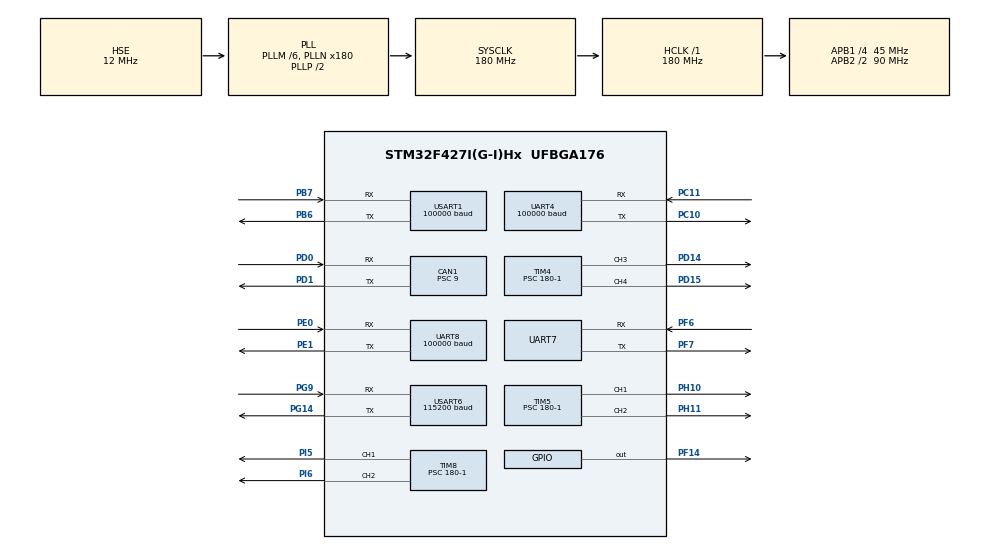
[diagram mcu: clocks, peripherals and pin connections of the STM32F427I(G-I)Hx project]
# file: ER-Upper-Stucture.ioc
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CAN1.BS1=CAN_BS1_3TQ
CAN1.CalculateBaudRate=1000000
CAN1.CalculateTimeBit=1000
CAN1.CalculateTimeQuantum=200.0
CAN1.Prescaler=9
Dma.Request0=USART1_RX
Dma.USART1_RX.0.Direction=DMA_PERIPH_TO_MEMORY
Dma.USART1_RX.0.FIFOMode=DMA_FIFOMODE_DISABLE
Dma.USART1_RX.0.Instance=DMA2_Stream2
Dma.USART1_RX.0.MemDataAlignment=DMA_MDATAALIGN_BYTE
Dma.USART1_RX.0.MemInc=DMA_MINC_ENABLE
Dma.USART1_RX.0.Mode=DMA_CIRCULAR
Dma.USART1_RX.0.PeriphDataAlignment=DMA_PDATAALIGN_BYTE
Dma.USART1_RX.0.PeriphInc=DMA_PINC_DISABLE
Dma.USART1_RX.0.Priority=DMA_PRIORITY_LOW
FREERTOS.INCLUDE_vTaskDelayUntil=1
FREERTOS.Tasks01=defaultTask,0,512,StartDefaultTask,As weak,NULL,Dynamic,NULL,NULL
FREERTOS.configENABLE_FPU=1
FREERTOS.configGENERATE_RUN_TIME_STATS=0
FREERTOS.configRECORD_STACK_HIGH_ADDRESS=1
FREERTOS.configTOTAL_HEAP_SIZE=65536
FREERTOS.configUSE_NEWLIB_REENTRANT=1
FREERTOS.configUSE_STATS_FORMATTING_FUNCTIONS=0
FREERTOS.configUSE_TRACE_FACILITY=0
Mcu.Family=STM32F4
Mcu.Name=STM32F427I(G-I)Hx
Mcu.Package=UFBGA176
NVIC.CAN1_RX0_IRQn=true\:0\:0\:true\:false\:true\:false\:true\:true\:true
NVIC.DMA2_Stream2_IRQn=true\:5\:0\:false\:false\:true\:true\:false\:true\:true
NVIC.PriorityGroup=NVIC_PRIORITYGROUP_4
NVIC.TIM7_IRQn=true\:15\:0\:false\:false\:true\:false\:false\:true\:true
NVIC.TimeBase=TIM7_IRQn
NVIC.TimeBaseIP=TIM7
NVIC.UART7_IRQn=true\:5\:0\:false\:false\:true\:true\:true\:true\:true
NVIC.UART8_IRQn=true\:5\:0\:false\:false\:true\:true\:true\:true\:true
NVIC.USART6_IRQn=true\:5\:0\:false\:false\:true\:true\:true\:true\:true
PA13.Mode=Serial_Wire
PA13.Signal=SYS_JTMS-SWDIO
PA14.Mode=Serial_Wire
PA14.Signal=SYS_JTCK-SWCLK
PB6.Mode=Asynchronous
PB6.Signal=USART1_TX
PB7.Mode=Asynchronous
PB7.Signal=USART1_RX
PC10.Mode=Asynchronous
PC10.Signal=UART4_TX
PC11.Mode=Asynchronous
PC11.Signal=UART4_RX
PD0.Mode=CAN_Activate
PD0.Signal=CAN1_RX
PD1.Mode=CAN_Activate
PD1.Signal=CAN1_TX
PD14.Signal=S_TIM4_CH3
PD15.Signal=S_TIM4_CH4
PE0.Mode=Asynchronous
PE0.Signal=UART8_RX
PE1.Mode=Asynchronous
PE1.Signal=UART8_TX
PF14.Signal=GPIO_Output
PF6.Mode=Asynchronous
PF6.Signal=UART7_RX
PF7.Mode=Asynchronous
PF7.Signal=UART7_TX
PG14.Mode=Asynchronous
PG14.Signal=USART6_TX
PG9.Mode=Asynchronous
PG9.Signal=USART6_RX
PH0/OSC_IN.Mode=HSE-External-Oscillator
PH0/OSC_IN.Signal=RCC_OSC_IN
PH1/OSC_OUT.Mode=HSE-External-Oscillator
PH1/OSC_OUT.Signal=RCC_OSC_OUT
PH10.Signal=S_TIM5_CH1
PH11.Signal=S_TIM5_CH2
PI5.Signal=S_TIM8_CH1
PI6.Signal=S_TIM8_CH2
ProjectManager.HeapSize=0x200
ProjectManager.StackSize=0x400
ProjectManager.TargetToolchain=Makefile
RCC.48MHZClocksFreq_Value=90000000
RCC.AHBFreq_Value=180000000
RCC.APB1CLKDivider=RCC_HCLK_DIV4
RCC.APB1Freq_Value=45000000
RCC.APB1TimFreq_Value=90000000
RCC.APB2CLKDivider=RCC_HCLK_DIV2
RCC.APB2Freq_Value=90000000
RCC.APB2TimFreq_Value=180000000
RCC.CortexFreq_Value=180000000
RCC.HCLKFreq_Value=180000000
RCC.HSE_VALUE=12000000
RCC.HSI_VALUE=16000000
RCC.LSE_VALUE=32768
RCC.PLLM=6
RCC.PLLN=180
RCC.PLLSourceVirtual=RCC_PLLSOURCE_HSE
RCC.SYSCLKFreq_VALUE=180000000
RCC.SYSCLKSource=RCC_SYSCLKSOURCE_PLLCLK
RCC.VCOOutputFreq_Value=360000000
SH.S_TIM4_CH3.0=TIM4_CH3,PWM Generation3 CH3
SH.S_TIM4_CH4.0=TIM4_CH4,PWM Generation4 CH4
SH.S_TIM5_CH1.0=TIM5_CH1,PWM Generation1 CH1
SH.S_TIM5_CH2.0=TIM5_CH2,PWM Generation2 CH2
SH.S_TIM8_CH1.0=TIM8_CH1,PWM Generation1 CH1
SH.S_TIM8_CH2.0=TIM8_CH2,PWM Generation2 CH2
TIM4.AutoReloadPreload=TIM_AUTORELOAD_PRELOAD_ENABLE
TIM4.Channel-PWM\ Generation3\ CH3=TIM_CHANNEL_3
TIM4.Channel-PWM\ Generation4\ CH4=TIM_CHANNEL_4
TIM4.Period=20000-1
TIM4.Prescaler=180-1
TIM5.AutoReloadPreload=TIM_AUTORELOAD_PRELOAD_ENABLE
TIM5.Channel-PWM\ Generation1\ CH1=TIM_CHANNEL_1
TIM5.Channel-PWM\ Generation2\ CH2=TIM_CHANNEL_2
TIM5.Period=20000-1
TIM5.Prescaler=180-1
TIM8.AutoReloadPreload=TIM_AUTORELOAD_PRELOAD_ENABLE
TIM8.Channel-PWM\ Generation1\ CH1=TIM_CHANNEL_1
TIM8.Channel-PWM\ Generation2\ CH2=TIM_CHANNEL_2
TIM8.Period=20000-1
TIM8.Prescaler=180-1
UART4.BaudRate=100000
UART4.VirtualMode=Asynchronous
UART7.VirtualMode=Asynchronous
UART8.BaudRate=100000
UART8.VirtualMode=Asynchronous
USART1.BaudRate=100000
USART1.VirtualMode=VM_ASYNC
USART6.BaudRate=115200
USART6.VirtualMode=VM_ASYNC
VP_CRC_VS_CRC.Mode=CRC_Activate
VP_FREERTOS_VS_CMSIS_V1.Mode=CMSIS_V1
VP_SYS_VS_tim7.Mode=TIM7
VP_TIM4_VS_ClockSourceINT.Mode=Internal
VP_TIM5_VS_ClockSourceINT.Mode=Internal
VP_TIM8_VS_ClockSourceINT.Mode=Internal
board=custom

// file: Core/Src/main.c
/* USER CODE BEGIN Header */
/**
 ******************************************************************************
 * @file           : main.c
 * @brief          : Main program body
 ******************************************************************************
 * @attention
 *
 * Copyright (c) 2023 STMicroelectronics.
 * All rights reserved.
 *
 * This software is licensed under terms that can be found in the LICENSE file
 * in the root directory of this software component.
 * If no LICENSE file comes with this software, it is provided AS-IS.
 *
 ******************************************************************************
 */
/* USER CODE END Header */
#include "main.h"
#include "cmsis_os.h"
#include "can.h"
#include "crc.h"
#include "dma.h"
#include "tim.h"
#include "usart.h"
#include "gpio.h"

void SystemClock_Config(void);
void MX_FREERTOS_Init(void);

int main(void)

{

  /* MCU Configuration--------------------------------------------------------*/

  /* Reset of all peripherals, Initializes the Flash interface and the Systick. */
  HAL_Init();

  /* Configure the system clock */
  SystemClock_Config();

  /* Initialize all configured peripherals */
  MX_GPIO_Init();
  MX_DMA_Init();
  MX_CAN1_Init();
  MX_CRC_Init();
  MX_USART1_UART_Init();
  MX_UART8_Init();
  MX_USART6_UART_Init();
  MX_UART7_Init();
  MX_TIM5_Init();
  MX_TIM8_Init();
  MX_UART4_Init();
  MX_TIM4_Init();

  /* Call init function for freertos objects (in freertos.c) */
  MX_FREERTOS_Init();

  /* Start scheduler */
  osKernelStart();
  /* We should never get here as control is now taken by the scheduler */
  /* Infinite loop */
    while (1) {

    /* USER CODE BEGIN 3 */
        HAL_Delay(1);
    }
  /* USER CODE END 3 */
}

void SystemClock_Config(void)
{
  RCC_OscInitTypeDef RCC_OscInitStruct = {0};
  RCC_ClkInitTypeDef RCC_ClkInitStruct = {0};

  /** Configure the main internal regulator output voltage
  */
  __HAL_RCC_PWR_CLK_ENABLE();
  __HAL_PWR_VOLTAGESCALING_CONFIG(PWR_REGULATOR_VOLTAGE_SCALE1);

  /** Initializes the RCC Oscillators according to the specified parameters
  * in the RCC_OscInitTypeDef structure.
  */
  RCC_OscInitStruct.OscillatorType = RCC_OSCILLATORTYPE_HSE;
  RCC_OscInitStruct.HSEState = RCC_HSE_ON;
  RCC_OscInitStruct.PLL.PLLState = RCC_PLL_ON;
  RCC_OscInitStruct.PLL.PLLSource = RCC_PLLSOURCE_HSE;
  RCC_OscInitStruct.PLL.PLLM = 6;
  RCC_OscInitStruct.PLL.PLLN = 180;
  RCC_OscInitStruct.PLL.PLLP = RCC_PLLP_DIV2;
  RCC_OscInitStruct.PLL.PLLQ = 4;
  if (HAL_RCC_OscConfig(&RCC_OscInitStruct) != HAL_OK)
  {
    Error_Handler();
  }

  /** Activate the Over-Drive mode
  */
  if (HAL_PWREx_EnableOverDrive() != HAL_OK)
  {
    Error_Handler();
  }

  /** Initializes the CPU, AHB and APB buses clocks
  */
  RCC_ClkInitStruct.ClockType = RCC_CLOCKTYPE_HCLK|RCC_CLOCKTYPE_SYSCLK
                              |RCC_CLOCKTYPE_PCLK1|RCC_CLOCKTYPE_PCLK2;
  RCC_ClkInitStruct.SYSCLKSource = RCC_SYSCLKSOURCE_PLLCLK;
  RCC_ClkInitStruct.AHBCLKDivider = RCC_SYSCLK_DIV1;
  RCC_ClkInitStruct.APB1CLKDivider = RCC_HCLK_DIV4;
  RCC_ClkInitStruct.APB2CLKDivider = RCC_HCLK_DIV2;

  if (HAL_RCC_ClockConfig(&RCC_ClkInitStruct, FLASH_LATENCY_5) != HAL_OK)
  {
    Error_Handler();
  }
}

void HAL_TIM_PeriodElapsedCallback(TIM_HandleTypeDef *htim)
{
  if (htim->Instance == TIM7) {
    HAL_IncTick();
  }
}

void Error_Handler(void)
{
    __disable_irq();
    while (1) {
    }
}
